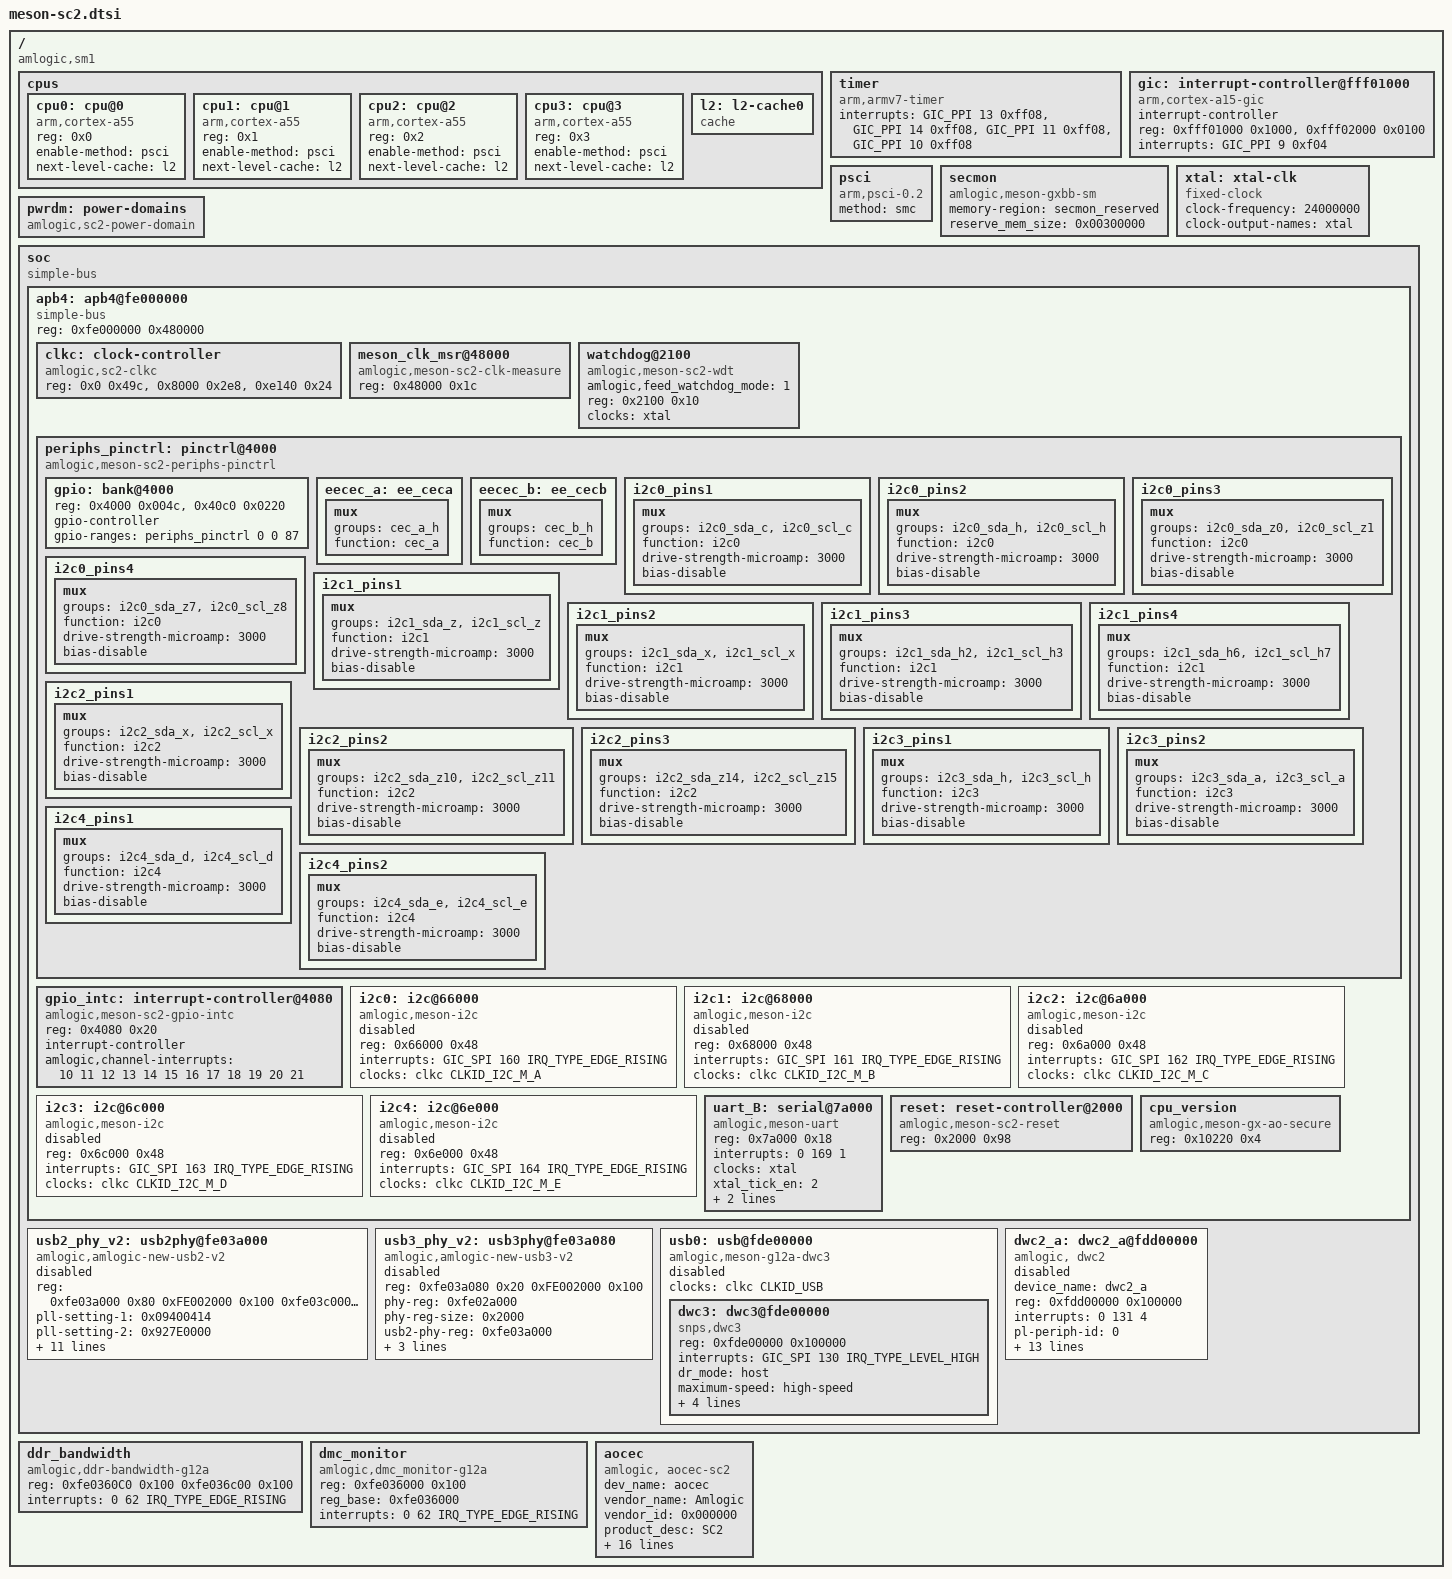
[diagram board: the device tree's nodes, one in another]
// SPDX-License-Identifier: (GPL-2.0+ OR MIT)
/*
 * Copyright (c) 2019 Amlogic, Inc. All rights reserved.
 */

#include <dt-bindings/interrupt-controller/irq.h>
#include <dt-bindings/clock/amlogic,sc2-clkc.h>
#include <dt-bindings/interrupt-controller/arm-gic.h>
#include <dt-bindings/clock/amlogic,sc2-clkc.h>
#include <dt-bindings/power/meson-sm1-power.h>
#include <dt-bindings/clock/amlogic,sm1-audio-clk.h>
#include <dt-bindings/gpio/gpio.h>
#include <dt-bindings/gpio/meson-sc2-gpio.h>
#include <dt-bindings/reset/amlogic,meson-sc2-reset.h>

/ {
	compatible = "amlogic,sm1";

	cpus {
		#address-cells = <0x1>;
		#size-cells = <0x0>;

		cpu0: cpu@0 {
			device_type = "cpu";
			compatible = "arm,cortex-a55","arm,armv8";
			reg = <0x0>;
			enable-method = "psci";
			next-level-cache = <&l2>;
		};

		cpu1: cpu@1 {
			device_type = "cpu";
			compatible = "arm,cortex-a55","arm,armv8";
			reg = <0x1>;
			enable-method = "psci";
			next-level-cache = <&l2>;
		};

		cpu2: cpu@2 {
			device_type = "cpu";
			compatible = "arm,cortex-a55","arm,armv8";
			reg = <0x2>;
			enable-method = "psci";
			next-level-cache = <&l2>;
		};

		cpu3: cpu@3 {
			device_type = "cpu";
			compatible = "arm,cortex-a55","arm,armv8";
			reg = <0x3>;
			enable-method = "psci";
			next-level-cache = <&l2>;
		};

		l2: l2-cache0 {
			compatible = "cache";
		};
	};

	timer {
		compatible = "arm,armv7-timer";
		interrupts = <GIC_PPI 13 0xff08>,
			     <GIC_PPI 14 0xff08>,
			     <GIC_PPI 11 0xff08>,
			     <GIC_PPI 10 0xff08>;
	};

	gic: interrupt-controller@fff01000 {
		compatible = "arm,cortex-a15-gic", "arm,cortex-a9-gic";
		#interrupt-cells = <3>;
		#address-cells = <0>;
		interrupt-controller;
		reg = <0xfff01000 0x1000>,
		      <0xfff02000 0x0100>;
		interrupts = <GIC_PPI 9 0xf04>;
	};

	psci {
		compatible = "arm,psci-0.2";
		method = "smc";
	};

	secmon {
		compatible = "amlogic,meson-gxbb-sm";
		memory-region = <&secmon_reserved>;
		reserve_mem_size = <0x00300000>;
	};

	xtal: xtal-clk {
		compatible = "fixed-clock";
		clock-frequency = <24000000>;
		clock-output-names = "xtal";
		#clock-cells = <0>;
	};

	pwrdm: power-domains {
		compatible = "amlogic,sc2-power-domain";
		#power-domain-cells = <1>;
		status = "okay";
	};

	soc: soc {
		compatible = "simple-bus";
		#address-cells = <1>;
		#size-cells = <1>;
		ranges;

		apb4: apb4@fe000000 {
			compatible = "simple-bus";
			reg = <0xfe000000 0x480000>;
			#address-cells = <1>;
			#size-cells = <1>;
			ranges = <0x0 0xfe000000 0x480000>;

			clkc: clock-controller {
				compatible = "amlogic,sc2-clkc";
				#clock-cells = <1>;
				reg = <0x0 0x49c>,
				      <0x8000 0x2e8>,
				      <0xe140 0x24>;
				reg-names = "basic", "pll",
					    "cpu_clk";
				status = "okay";
			};

			meson_clk_msr@48000 {
				compatible = "amlogic,meson-sc2-clk-measure";
				reg = <0x48000 0x1c>;
			};

			watchdog@2100 {
				compatible = "amlogic,meson-sc2-wdt";
				status = "okay";
				/* 0:userspace, 1:kernel */
				amlogic,feed_watchdog_mode = <1>;
				reg = <0x2100 0x10>;
				clocks = <&xtal>;
			};

			periphs_pinctrl: pinctrl@4000 {
				compatible = "amlogic,meson-sc2-periphs-pinctrl";
				#address-cells = <1>;
				#size-cells = <1>;
				ranges;

				gpio: bank@4000 {
					reg = <0x4000 0x004c>,
					      <0x40c0 0x0220>;
					reg-names = "mux", "gpio";
					gpio-controller;
					#gpio-cells = <2>;
					gpio-ranges = <&periphs_pinctrl 0 0 87>;
				};

				eecec_a: ee_ceca {
					mux {
						groups = "cec_a_h";
						function = "cec_a";
					};
				};

				eecec_b: ee_cecb {
					mux {
						groups = "cec_b_h";
						function = "cec_b";
					};
				};
			};

			gpio_intc: interrupt-controller@4080 {
				compatible = "amlogic,meson-sc2-gpio-intc",
					     "amlogic,meson-gpio-intc";
				reg = <0x4080 0x20>;
				interrupt-controller;
				#interrupt-cells = <2>;
				amlogic,channel-interrupts =
					<10 11 12 13 14 15 16 17 18 19 20 21>;
			};

			i2c0: i2c@66000 {
				compatible = "amlogic,meson-i2c";
				reg = <0x66000 0x48>;
				interrupts = <GIC_SPI 160 IRQ_TYPE_EDGE_RISING>;
				#address-cells = <1>;
				#size-cells = <0>;
				clocks = <&clkc CLKID_I2C_M_A>;
				status = "disabled";
			};

			i2c1: i2c@68000 {
				compatible = "amlogic,meson-i2c";
				reg = <0x68000 0x48>;
				interrupts = <GIC_SPI 161 IRQ_TYPE_EDGE_RISING>;
				#address-cells = <1>;
				#size-cells = <0>;
				clocks = <&clkc CLKID_I2C_M_B>;
				status = "disabled";
			};

			i2c2: i2c@6a000 {
				compatible = "amlogic,meson-i2c";
				reg = <0x6a000 0x48>;
				interrupts = <GIC_SPI 162 IRQ_TYPE_EDGE_RISING>;
				#address-cells = <1>;
				#size-cells = <0>;
				clocks = <&clkc CLKID_I2C_M_C>;
				status = "disabled";
			};

			i2c3: i2c@6c000 {
				compatible = "amlogic,meson-i2c";
				reg = <0x6c000 0x48>;
				interrupts = <GIC_SPI 163 IRQ_TYPE_EDGE_RISING>;
				#address-cells = <1>;
				#size-cells = <0>;
				clocks = <&clkc CLKID_I2C_M_D>;
				status = "disabled";
			};

			i2c4: i2c@6e000 {
				compatible = "amlogic,meson-i2c";
				reg = <0x6e000 0x48>;
				interrupts = <GIC_SPI 164 IRQ_TYPE_EDGE_RISING>;
				#address-cells = <1>;
				#size-cells = <0>;
				clocks = <&clkc CLKID_I2C_M_E>;
				status = "disabled";
			};

			uart_B: serial@7a000 {
				compatible = "amlogic,meson-uart";
				reg = <0x7a000 0x18>;
				interrupts = <0 169 1>;
				status = "okay";
				clocks = <&xtal>;
				clock-names = "clk_uart";
				xtal_tick_en = <2>;
				fifosize = < 64 >;
				pinctrl-names = "default";
				/*pinctrl-0 = <&ao_uart_pins>;*/
				support-sysrq = <1>;  /* 0 not support*/
			};

			reset: reset-controller@2000 {
				compatible = "amlogic,meson-sc2-reset";
				reg = <0x2000 0x98>;
				#reset-cells = <1>;
			};

			cpu_version {
				compatible = "amlogic,meson-gx-ao-secure", "syscon";
				reg=<0x10220 0x4>;
			};
		};

		usb2_phy_v2: usb2phy@fe03a000 {
			compatible = "amlogic,amlogic-new-usb2-v2";
			status = "disable";
			#phy-cells = <0>;
			reg = <0xfe03a000 0x80
					0xFE002000 0x100
					0xfe03c000 0x2000
					0xfe03e000 0x2000>;
			pll-setting-1 = <0x09400414>;
			pll-setting-2 = <0x927E0000>;
			pll-setting-3 = <0xac5f69e5>;
			pll-setting-4 = <0xfe18>;
			pll-setting-5 = <0x8000fff>;
			pll-setting-6 = <0x78000>;
			pll-setting-7 = <0xe0004>;
			pll-setting-8 = <0xe000c>;
			version = <2>;
			/*power-domains = <&pwrdm PDID_USB_COMB>;*/
			phy20-reset-level-bit = <8>;
			phy21-reset-level-bit = <9>;
			usb-reset-bit = <4>;
			reset_level = <0x40>;
		};

		usb3_phy_v2: usb3phy@fe03a080 {
			compatible = "amlogic,amlogic-new-usb3-v2";
			status = "disable";
			#phy-cells = <0>;
			reg = <0xfe03a080 0x20
				0xFE002000 0x100>;
			phy-reg = <0xfe02a000>;
			phy-reg-size = <0x2000>;
			usb2-phy-reg = <0xfe03a000>;
			usb2-phy-reg-size = <0x80>;
			clocks = <&clkc CLKID_PCIE_PLL>;
			interrupts = <0 129 4>;
			clock-names = "pcie_refpll";
		};

		usb0: usb@fde00000 {
			compatible = "amlogic,meson-g12a-dwc3";
			status = "disabled";
			#address-cells = <1>;
			#size-cells = <1>;
			ranges;

			clocks = <&clkc CLKID_USB>;
			clock-names = "usb_general";

			dwc3: dwc3@fde00000 {
				compatible = "snps,dwc3";
				reg = <0xfde00000 0x100000>;
				interrupts = <GIC_SPI 130 IRQ_TYPE_LEVEL_HIGH>;
				dr_mode = "host";
				maximum-speed = "high-speed";
				snps,dis_u2_susphy_quirk;
				snps,quirk-frame-length-adjustment;
				usb-phy = <&usb2_phy_v2>, <&usb3_phy_v2>;
				clocks = <&clkc CLKID_USB>;
				clock-names = "usb_general";
				/*usb5v-supply = <&ao_5v>;*/
				/*usb3v3-supply = <&vddao_3v3>;*/
				/*usb1v8-supply = <&vddio_ao1v8>;*/
			};
		};

		dwc2_a: dwc2_a@fdd00000 {
			compatible = "amlogic, dwc2";
			status = "disable";
			device_name = "dwc2_a";
			reg = <0xfdd00000 0x100000>;
			interrupts = <0 131 4>;
			pl-periph-id = <0>; /** lm name */
			clock-src = "usb0"; /** clock src */
			port-id = <0>;  /** ref to mach/usb.h */
			port-type = <2>;        /** 0: otg, 1: host, 2: slave */
			port-speed = <0>; /** 0: default, high, 1: full */
			port-config = <0>; /** 0: default */
			/*0:default,1:single,2:incr,3:incr4,4:incr8,5:incr16,6:disable*/
			port-dma = <0>;
			port-id-mode = <0>; /** 0: hardware, 1: sw_host, 2: sw_slave*/
			usb-fifo = <728>;
			cpu-type = "v2";
			phy-reg = <0xfe03a000>;
			phy-reg-size = <0xa0>;
			/** phy-interface: 0x0: amlogic phy, 0x1: synopsys phy **/
			phy-interface = <0x2>;
			clocks = <&clkc CLKID_USB
						&clkc CLKID_USB1_TO_DDR>;
			clock-names = "usb_general",
						"usb1";
		};

	};

	ddr_bandwidth {
		compatible = "amlogic,ddr-bandwidth-g12a";
		status = "okay";
		reg = <0xfe0360C0 0x100
		       0xfe036c00 0x100>;
		interrupts = <0 62 IRQ_TYPE_EDGE_RISING>;
		interrupt-names = "ddr_bandwidth";
	};
	dmc_monitor {
		compatible = "amlogic,dmc_monitor-g12a";
		status = "okay";
		reg = <0xfe036000 0x100>;
		reg_base = <0xfe036000>;
		interrupts = <0 62 IRQ_TYPE_EDGE_RISING>;
	};

	aocec: aocec {
		compatible = "amlogic, aocec-sc2";
		dev_name = "aocec";
		status = "okay";
		vendor_name = "Amlogic"; /* Max Chars: 8     */
		/* Refer to the following URL at:
		 * http://standards.ieee.org/develop/regauth/oui/oui.txt
		 */
		vendor_id = <0x000000>;
		product_desc = "SC2"; /* Max Chars: 16    */
		cec_osd_string = "AML_MBOX"; /* Max Chars: 14    */
		cec_version = <5>;/*5:1.4;6:2.0*/
		port_num = <1>;
		output = <1>;
		cec_sel = <1>;/*1:use one ip, 2:use 2 ip*/
		ee_cec;
		arc_port_mask = <0x1>;
		interrupts = <GIC_SPI 180 IRQ_TYPE_EDGE_RISING/*0:snps*/
			GIC_SPI 179 IRQ_TYPE_EDGE_RISING>;/*1:ts*/
		interrupt-names = "hdmi_aocecb","hdmi_aocec";
		pinctrl-names = "default","hdmitx_aocecb","cec_pin_sleep";
		pinctrl-0=<&eecec_a>;
		pinctrl-1=<&eecec_b>;
		pinctrl-2=<&eecec_b>;
		clocks = <&clkc CLKID_CECA_32K_CLKOUT>,
			<&clkc CLKID_CECB_32K_CLKOUT>;
		clock-names = "ceca_clk","cecb_clk";
		reg = <0xfe044000 0x2ff
		       0xfe010000 0xfff
		       0xfe000000 0xfff>;
		reg-names = "ao","periphs","clock";/*ao_exit hdmirx hhi*/
	};

};

&periphs_pinctrl {
	i2c0_pins1:i2c0_pins1 {
		mux {
			groups = "i2c0_sda_c",
				"i2c0_scl_c";
			function = "i2c0";
			drive-strength-microamp = <3000>;
			bias-disable;
		};
	};

	i2c0_pins2:i2c0_pins2 {
		mux {
			groups = "i2c0_sda_h",
				"i2c0_scl_h";
			function = "i2c0";
			drive-strength-microamp = <3000>;
			bias-disable;
		};
	};

	i2c0_pins3:i2c0_pins3 {
		mux {
			groups = "i2c0_sda_z0",
				"i2c0_scl_z1";
			function = "i2c0";
			drive-strength-microamp = <3000>;
			bias-disable;
		};
	};

	i2c0_pins4:i2c0_pins4 {
		mux {
			groups = "i2c0_sda_z7",
				"i2c0_scl_z8";
			function = "i2c0";
			drive-strength-microamp = <3000>;
			bias-disable;

		};
	};

	i2c1_pins1:i2c1_pins1 {
		mux {
			groups = "i2c1_sda_z",
				"i2c1_scl_z";
			function = "i2c1";
			drive-strength-microamp = <3000>;
			bias-disable;
		};
	};

	i2c1_pins2:i2c1_pins2 {
		mux {
			groups = "i2c1_sda_x",
				"i2c1_scl_x";
			function = "i2c1";
			drive-strength-microamp = <3000>;
			bias-disable;
		};
	};

	i2c1_pins3:i2c1_pins3 {
		mux {
			groups = "i2c1_sda_h2",
				"i2c1_scl_h3";
			function = "i2c1";
			drive-strength-microamp = <3000>;
			bias-disable;
		};
	};

	i2c1_pins4:i2c1_pins4 {
		mux {
			groups = "i2c1_sda_h6",
				"i2c1_scl_h7";
			function = "i2c1";
			drive-strength-microamp = <3000>;
			bias-disable;
		};
	};

	i2c2_pins1:i2c2_pins1 {
		mux {
			groups = "i2c2_sda_x",
				"i2c2_scl_x";
			function = "i2c2";
			drive-strength-microamp = <3000>;
			bias-disable;
		};
	};

	i2c2_pins2:i2c2_pins2 {
		mux {
			groups = "i2c2_sda_z10",
				"i2c2_scl_z11";
			function = "i2c2";
			drive-strength-microamp = <3000>;
			bias-disable;
		};
	};

	i2c2_pins3:i2c2_pins3 {
		mux {
			groups = "i2c2_sda_z14",
				"i2c2_scl_z15";
			function = "i2c2";
			drive-strength-microamp = <3000>;
			bias-disable;
		};
	};

	i2c3_pins1:i2c3_pins1 {
		mux {
			groups = "i2c3_sda_h",
				"i2c3_scl_h";
			function = "i2c3";
			drive-strength-microamp = <3000>;
			bias-disable;
		};
	};

	i2c3_pins2:i2c3_pins2 {
		mux {
			groups = "i2c3_sda_a",
				"i2c3_scl_a";
			function = "i2c3";
			drive-strength-microamp = <3000>;
			bias-disable;
		};
	};

	i2c4_pins1:i2c4_pins1 {
		mux {
			groups = "i2c4_sda_d",
				"i2c4_scl_d";
			function = "i2c4";
			drive-strength-microamp = <3000>;
			bias-disable;
		};
	};

	i2c4_pins2:i2c4_pins2 {
		mux {
			groups = "i2c4_sda_e",
				"i2c4_scl_e";
			function = "i2c4";
			drive-strength-microamp = <3000>;
			bias-disable;
		};
	};
};
